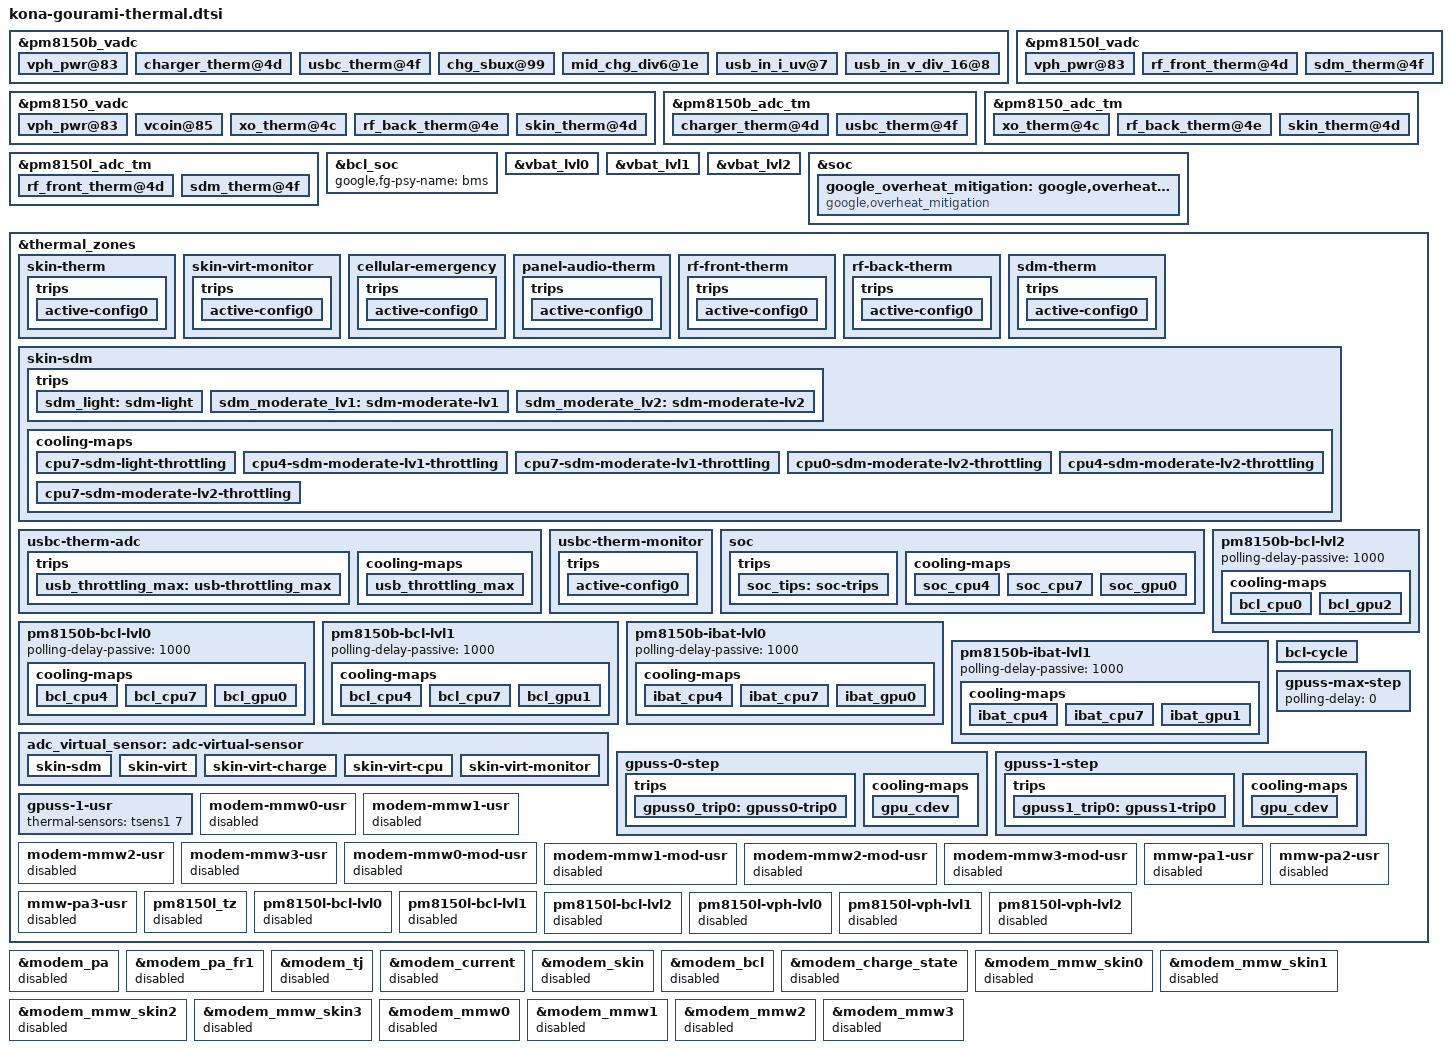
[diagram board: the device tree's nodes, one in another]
// SPDX-License-Identifier: GPL-2.0
/* Copyright (c) 2022, The Linux Foundation. All rights reserved.
 *
 * This program is free software; you can redistribute it and/or modify
 * it under the terms of the GNU General Public License version 2 and
 * only version 2 as published by the Free Software Foundation.
 *
 * This program is distributed in the hope that it will be useful,
 * but WITHOUT ANY WARRANTY; without even the implied warranty of
 * MERCHANTABILITY or FITNESS FOR A PARTICULAR PURPOSE.  See the
 * GNU General Public License for more details.
 */

#include <dt-bindings/thermal/thermal.h>

&pm8150b_vadc {
	#address-cells = <1>;
	#size-cells = <0>;

	vph_pwr@83 {
		reg = <ADC_VPH_PWR>;
		label = "vph_pwr";
		qcom,pre-scaling = <1 3>;
	};

	charger_therm@4d {
		reg = <ADC_AMUX_THM1_PU2>;
		label = "charger_therm";
		qcom,ratiometric;
		qcom,hw-settle-time = <200>;
		qcom,pre-scaling = <1 1>;
	};

	usbc_therm@4f {
		reg = <ADC_AMUX_THM3_PU2>;
		label = "usbc_therm";
		qcom,ratiometric;
		qcom,hw-settle-time = <200>;
		qcom,pre-scaling = <1 1>;
	};

	chg_sbux@99 {
		reg = <ADC_SBUx>;
		label = "chg_sbux";
		qcom,pre-scaling = <1 3>;
	};

	mid_chg_div6@1e {
		reg = <ADC_MID_CHG_DIV6>;
		label = "chg_mid";
		qcom,pre-scaling = <1 6>;
	};

	usb_in_i_uv@7 {
		reg = <ADC_USB_IN_I>;
		label = "usb_in_i_uv";
		qcom,pre-scaling = <1 1>;
	};

	usb_in_v_div_16@8 {
		reg = <ADC_USB_IN_V_16>;
		label = "usb_in_v_div_16";
		qcom,pre-scaling = <1 16>;
	};

	/delete-node/ smb1390_therm;
	/delete-node/ smb1355_therm;
};

&pm8150_vadc {
	#address-cells = <1>;
	#size-cells = <0>;

	vph_pwr@83 {
		reg = <ADC_VPH_PWR>;
		label = "vph_pwr";
		qcom,pre-scaling = <1 3>;
	};

	vcoin@85 {
		reg = <ADC_VCOIN>;
		label = "vcoin";
		qcom,pre-scaling = <1 3>;
	};

	xo_therm@4c {
		reg = <ADC_XO_THERM_PU2>;
		label = "xo_therm";
		qcom,ratiometric;
		qcom,hw-settle-time = <200>;
		qcom,pre-scaling = <1 1>;
	};

	rf_back_therm@4e {
		reg = <ADC_AMUX_THM2_PU2>;
		label = "rf_back_therm";
		qcom,ratiometric;
		qcom,hw-settle-time = <200>;
		qcom,pre-scaling = <1 1>;
	};

	skin_therm@4d {
		reg = <ADC_AMUX_THM1_PU2>;
		label = "skin_therm";
		qcom,ratiometric;
		qcom,hw-settle-time = <200>;
		qcom,pre-scaling = <1 1>;
	};
};

&pm8150l_vadc {
	#address-cells = <1>;
	#size-cells = <0>;

	vph_pwr@83 {
		reg = <ADC_VPH_PWR>;
		label = "vph_pwr";
		qcom,pre-scaling = <1 3>;
	};

	rf_front_therm@4d {
		reg = <ADC_AMUX_THM1_PU2>;
		label = "rf_front_therm";
		qcom,ratiometric;
		qcom,hw-settle-time = <200>;
		qcom,pre-scaling = <1 1>;
	};

	sdm_therm@4f {
		reg = <ADC_AMUX_THM3_PU2>;
		label = "sdm_therm";
		qcom,ratiometric;
		qcom,hw-settle-time = <200>;
		qcom,pre-scaling = <1 1>;
	};
};

&pm8150b_adc_tm {
	#address-cells = <1>;
	#size-cells = <0>;

	io-channels = <&pm8150b_vadc ADC_AMUX_THM1_PU2>,
			<&pm8150b_vadc ADC_AMUX_THM3_PU2>;

	/* Channel nodes */
	charger_therm@4d {
		reg = <ADC_AMUX_THM1_PU2>;
		qcom,ratiometric;
		qcom,hw-settle-time = <200>;
	};

	usbc_therm@4f {
		reg = <ADC_AMUX_THM3_PU2>;
		qcom,ratiometric;
		qcom,hw-settle-time = <200>;
	};
};

&pm8150_adc_tm {
	#address-cells = <1>;
	#size-cells = <0>;

	io-channels = <&pm8150_vadc ADC_XO_THERM_PU2>,
			<&pm8150_vadc ADC_AMUX_THM2_PU2>,
			<&pm8150_vadc ADC_AMUX_THM1_PU2>;

	xo_therm@4c {
		reg = <ADC_XO_THERM_PU2>;
		qcom,ratiometric;
		qcom,hw-settle-time = <200>;
	};

	rf_back_therm@4e {
		reg = <ADC_AMUX_THM2_PU2>;
		qcom,ratiometric;
		qcom,hw-settle-time = <200>;
	};

	skin_therm@4d {
		reg = <ADC_AMUX_THM1_PU2>;
		qcom,ratiometric;
		qcom,hw-settle-time = <200>;
	};
};

&pm8150l_adc_tm {
	#address-cells = <1>;
	#size-cells = <0>;

	io-channels = <&pm8150l_vadc ADC_AMUX_THM1_PU2>,
			<&pm8150l_vadc ADC_AMUX_THM3_PU2>;

	/* Channel nodes */
	rf_front_therm@4d {
		reg = <ADC_AMUX_THM1_PU2>;
		qcom,ratiometric;
		qcom,hw-settle-time = <200>;
	};

	sdm_therm@4f {
		reg = <ADC_AMUX_THM3_PU2>;
		qcom,ratiometric;
		qcom,hw-settle-time = <200>;
	};
};

&bcl_soc {
	google,fg-psy-name = "bms";
};

&vbat_lvl0 {
	temperature = <3200>;
	hysteresis = <200>;
	type = "passive";
};

&vbat_lvl1 {
	temperature = <3100>;
	hysteresis = <200>;
	type = "passive";
};

&vbat_lvl2 {
	temperature = <3000>;
	hysteresis = <200>;
	type = "passive";
};

&soc {
	google_overheat_mitigation: google,overheat_mitigation {
		compatible = "google,overheat_mitigation";
		google,port-overheat-work-interval = <2000>;
		google,begin-mitigation-temp = <480>;
		google,end-mitigation-temp = <400>;
		/* Must maintain < 1/15 duty cycle */
		google,polling-freq = <3>;
		#cooling-cells = <2>;
	};
};

&thermal_zones {
	/* Bring up common thermal zones for Gourami */
	skin-therm {
		polling-delay-passive = <0>;
		polling-delay = <0>;
		thermal-governor = "user_space";
		thermal-sensors = <&pm8150_adc_tm ADC_AMUX_THM1_PU2>;
		wake-capable-sensor;
		trips {
			active-config0 {
				temperature = <125000>;
				hysteresis = <1000>;
				type = "passive";
			};
		};
	};

	skin-virt-monitor {
		polling-delay-passive = <0>;
		polling-delay = <0>;
		thermal-governor = "user_space";
		wake-capable-sensor;
		//disable-thermal-zone;
		trips {
			active-config0 {
				temperature = <125000>;
				hysteresis = <1000>;
				type = "passive";
			};
		};
	};

	cellular-emergency {
		polling-delay-passive = <0>;
		polling-delay = <0>;
		thermal-governor = "user_space";
		thermal-sensors = <&pm8150l_adc_tm ADC_AMUX_THM1_PU2>;
		wake-capable-sensor;
		trips {
			active-config0 {
				temperature = <125000>;
				hysteresis = <1000>;
				type = "passive";
			};
		};
	};

	panel-audio-therm {
		polling-delay-passive = <0>;
		polling-delay = <0>;
		thermal-governor = "user_space";
		thermal-sensors = <&pm8150l_adc_tm ADC_AMUX_THM1_PU2>;
		wake-capable-sensor;
		trips {
			active-config0 {
				temperature = <125000>;
				hysteresis = <1000>;
				type = "passive";
			};
		};
	};

	rf-front-therm {
		polling-delay-passive = <0>;
		polling-delay = <0>;
		thermal-governor = "user_space";
		thermal-sensors = <&pm8150l_adc_tm ADC_AMUX_THM1_PU2>;
		wake-capable-sensor;
		trips {
			active-config0 {
				temperature = <125000>;
				hysteresis = <1000>;
				type = "passive";
			};
		};
	};

	rf-back-therm {
		polling-delay-passive = <0>;
		polling-delay = <0>;
		thermal-governor = "user_space";
		thermal-sensors = <&pm8150_adc_tm ADC_AMUX_THM2_PU2>;
		wake-capable-sensor;
		trips {
			active-config0 {
				temperature = <125000>;
				hysteresis = <1000>;
				type = "passive";
			};
		};
	};

	sdm-therm {
		polling-delay-passive = <0>;
		polling-delay = <0>;
		thermal-governor = "user_space";
		thermal-sensors = <&pm8150l_adc_tm ADC_AMUX_THM3_PU2>;
		wake-capable-sensor;
		trips {
			active-config0 {
				temperature = <125000>;
				hysteresis = <1000>;
				type = "passive";
			};
		};
	};

	skin-sdm {
		polling-delay-passive = <2000>;
		polling-delay = <0>;
		thermal-governor = "step_wise";
		wake-capable-sensor;
		trips {
			sdm_light: sdm-light {
				temperature = <63000>;
				hysteresis = <2000>;
				type = "passive";
			};
			sdm_moderate_lv1: sdm-moderate-lv1 {
				temperature = <65000>;
				hysteresis = <2000>;
				type = "passive";
			};
			sdm_moderate_lv2: sdm-moderate-lv2 {
				temperature = <67000>;
				hysteresis = <2000>;
				type = "passive";
			};
		};
		cooling-maps {
			/* sdm light throttling */
			cpu7-sdm-light-throttling {
				trip = <&sdm_light>;
				cooling-device =
				<&CPU7 1 1>;
			};
			/* sdm moderate throttling level 1 */
			cpu4-sdm-moderate-lv1-throttling {
				trip = <&sdm_moderate_lv1>;
				cooling-device =
				<&CPU4 1 2>;
			};
			cpu7-sdm-moderate-lv1-throttling {
				trip = <&sdm_moderate_lv1>;
				cooling-device =
				<&CPU7 2 4>;
			};
			/* sdm moderate throttling level 2 */
			cpu0-sdm-moderate-lv2-throttling {
				trip = <&sdm_moderate_lv2>;
				cooling-device =
				<&CPU0 1 2>;
			};
			cpu4-sdm-moderate-lv2-throttling {
				trip = <&sdm_moderate_lv2>;
				cooling-device =
				<&CPU4 2 3>;
			};
			cpu7-sdm-moderate-lv2-throttling {
				trip = <&sdm_moderate_lv2>;
				cooling-device =
				<&CPU7 4 5>;
			};
		};
	};

	usbc-therm-adc {
		polling-delay-passive = <0>;
		polling-delay = <0>;
		thermal-governor = "step_wise";
		thermal-sensors = <&pm8150b_adc_tm ADC_AMUX_THM3_PU2>;
		wake-capable-sensor;
		trips {
			usb_throttling_max: usb-throttling_max {
				temperature = <48000>;
				hysteresis = <10000>;
				type = "passive";
			};
		};
		cooling-maps {
			usb_throttling_max {
				trip = <&usb_throttling_max>;
				cooling-device =
					<&google_overheat_mitigation
					THERMAL_MAX_LIMIT THERMAL_MAX_LIMIT>;
			};
		};
	};

	usbc-therm-monitor {
		polling-delay-passive = <0>;
		polling-delay = <0>;
		thermal-governor = "user_space";
		thermal-sensors = <&pm8150b_adc_tm ADC_AMUX_THM3_PU2>;
		wake-capable-sensor;
		trips {
			active-config0 {
				temperature = <125000>;
				hysteresis = <1000>;
				type = "passive";
			};
		};
	};

	soc {
		polling-delay-passive = <60000>;
		polling-delay = <0>;
		thermal-governor = "low_limits_cap";
		thermal-sensors = <&bcl_soc>;
		tracks-low;
		wake-capable-sensor;

		trips {
			soc_tips: soc-trips {
				temperature = <10>;
				hysteresis = <0>;
				type = "passive";
			};
		};
		cooling-maps {
			soc_cpu4 {
				trip = <&soc_tips>;
				cooling-device =
					<&CPU4 11 11>;
			};
			soc_cpu7 {
				trip = <&soc_tips>;
				cooling-device =
					<&CPU7 11 11>;
			};
			soc_gpu0 {
				trip = <&soc_tips>;
				cooling-device = <&msm_gpu 4 4>;
			};
		};
	};

	pm8150b-bcl-lvl0 {
		polling-delay-passive = <1000>;
		cooling-maps {
			bcl_cpu4 {
				trip = <&b_bcl_lvl0>;
				cooling-device =
					<&CPU4 11 11>;
			};
			bcl_cpu7 {
				trip = <&b_bcl_lvl0>;
				cooling-device =
					<&CPU7 11 11>;
			};
			bcl_gpu0 {
				trip = <&b_bcl_lvl0>;
				cooling-device = <&msm_gpu 4 4>;
			};
		};
	};

	pm8150b-bcl-lvl1 {
		polling-delay-passive = <1000>;
		cooling-maps {
			bcl_cpu4 {
				trip = <&b_bcl_lvl1>;
				cooling-device =
					<&CPU4 THERMAL_MAX_LIMIT
					THERMAL_MAX_LIMIT>;
			};
			bcl_cpu7 {
				trip = <&b_bcl_lvl1>;
				cooling-device =
					<&CPU7 THERMAL_MAX_LIMIT
					THERMAL_MAX_LIMIT>;
			};
			bcl_gpu1 {
				trip = <&b_bcl_lvl1>;
				cooling-device = <&msm_gpu 6 6>;
			};
		};
	};

	pm8150b-bcl-lvl2 {
		polling-delay-passive = <1000>;
		cooling-maps {
			bcl_cpu0 {
				trip = <&b_bcl_lvl2>;
				cooling-device =
					<&CPU0 6 6>;
			};
			bcl_gpu2 {
				trip = <&b_bcl_lvl2>;
				cooling-device = <&msm_gpu THERMAL_MAX_LIMIT
							THERMAL_MAX_LIMIT>;
			};
		};
	};

	pm8150b-ibat-lvl0 {
		polling-delay-passive = <1000>;
		cooling-maps {
			ibat_cpu4 {
				trip = <&ibat_lvl0>;
				cooling-device =
					<&CPU4 11 11>;
			};
			ibat_cpu7 {
				trip = <&ibat_lvl0>;
				cooling-device =
					<&CPU7 11 11>;
			};
			ibat_gpu0 {
				trip = <&ibat_lvl0>;
				cooling-device = <&msm_gpu 4 4>;
			};
		};
	};

	pm8150b-ibat-lvl1 {
		polling-delay-passive = <1000>;
		cooling-maps {
			ibat_cpu4 {
				trip = <&ibat_lvl1>;
				cooling-device =
					<&CPU4 THERMAL_MAX_LIMIT
					THERMAL_MAX_LIMIT>;
			};
			ibat_cpu7 {
				trip = <&ibat_lvl1>;
				cooling-device =
					<&CPU7 THERMAL_MAX_LIMIT
					THERMAL_MAX_LIMIT>;
			};
			ibat_gpu1 {
				trip = <&ibat_lvl1>;
				cooling-device = <&msm_gpu 6 6>;
			};
		};
	};

	bcl-cycle {
		polling-delay-passive = <60000>;
		polling-delay = <0>;
		thermal-sensors = <&google_battery>;
	};

	adc_virtual_sensor: adc-virtual-sensor {
	};

	gpuss-max-step {
		polling-delay = <0>;
	};

	gpuss-0-step {
		polling-delay-passive = <10>;
		polling-delay = <0>;
		thermal-sensors = <&tsens0 15>;
		thermal-governor = "step_wise";
		wake-capable-sensor;
		trips {
			gpuss0_trip0: gpuss0-trip0 {
				temperature = <95000>;
				hysteresis = <1000>;
				type = "passive";
			};
		};
		cooling-maps {
			gpu_cdev {
				trip = <&gpuss0_trip0>;
				cooling-device = <&msm_gpu THERMAL_NO_LIMIT
							THERMAL_NO_LIMIT>;
			};
		};
	};

	gpuss-1-step {
		polling-delay-passive = <10>;
		polling-delay = <0>;
		thermal-sensors = <&tsens1 8>;
		thermal-governor = "step_wise";
		wake-capable-sensor;
		trips {
			gpuss1_trip0: gpuss1-trip0 {
				temperature = <95000>;
				hysteresis = <1000>;
				type = "passive";
			};
		};
		cooling-maps {
			gpu_cdev {
				trip = <&gpuss1_trip0>;
				cooling-device = <&msm_gpu THERMAL_NO_LIMIT
							THERMAL_NO_LIMIT>;
			};
		};
	};

	gpuss-1-usr {
		thermal-sensors = <&tsens1 7>;
	};

	/* Remove redundant QCT thermal zones */
	modem-mmw0-usr {
		status = "disabled";
	};

	modem-mmw1-usr {
		status = "disabled";
	};

	modem-mmw2-usr {
		status = "disabled";
	};

	modem-mmw3-usr {
		status = "disabled";
	};

	modem-mmw0-mod-usr {
		status = "disabled";
	};

	modem-mmw1-mod-usr {
		status = "disabled";
	};

	modem-mmw2-mod-usr {
		status = "disabled";
	};

	modem-mmw3-mod-usr {
		status = "disabled";
	};

	mmw-pa1-usr {
		status = "disabled";
	};

	mmw-pa2-usr {
		status = "disabled";
	};

	mmw-pa3-usr {
		status = "disabled";
	};

	pm8150l_tz {
		status = "disabled";
	};

	/* Disable PM8150l BCL */
	pm8150l-bcl-lvl0 {
		status = "disabled";
	};

	pm8150l-bcl-lvl1 {
		status = "disabled";
	};

	pm8150l-bcl-lvl2 {
		status = "disabled";
	};

	pm8150l-vph-lvl0 {
		status = "disabled";
	};

	pm8150l-vph-lvl1 {
		status = "disabled";
	};

	pm8150l-vph-lvl2 {
		status = "disabled";
	};
};

&adc_virtual_sensor {
	skin-sdm {
		logic = "weight";
		num_sensors = <2>;
		sensor-names = "skin-therm", "sdm-therm";
		coefficients = <1 1>;
		avg-offset = <0>;
		avg-denominator = <2>;
	};

	skin-virt {
		logic = "weight";
		num_sensors = <2>;
		sensor-names = "skin-therm", "usbc-therm-adc";
		coefficients = <1 1>;
		avg-offset = <(-2500)>;
		avg-denominator = <2>;
	};

	skin-virt-charge {
		logic = "weight";
		num_sensors = <3>;
		sensor-names = "skin-therm", "sdm-therm", "usbc-therm-adc";
		coefficients = <1 1 2>;
		avg-offset = <0>;
		avg-denominator = <4>;
	};

	skin-virt-cpu {
		logic = "weight";
		num_sensors = <2>;
		sensor-names = "skin-therm", "usbc-therm-adc";
		coefficients = <1 1>;
		avg-offset = <(-2500)>;
		avg-denominator = <2>;
	};

	skin-virt-monitor {
		logic = "weight";
		num_sensors = <2>;
		sensor-names = "skin-therm", "usbc-therm-adc";
		coefficients = <1 1>;
		avg-offset = <(-2500)>;
		avg-denominator = <2>;
	};
};

/* Remove redundant QCT thermal zones */
&modem_pa {
	status = "disabled";
};

&modem_pa_fr1 {
	status = "disabled";
};

&modem_tj {
	status = "disabled";
};

&modem_current {
	status = "disabled";
};

&modem_skin {
	status = "disabled";
};

&modem_bcl {
	status = "disabled";
};

&modem_charge_state {
	status = "disabled";
};

&modem_mmw_skin0 {
	status = "disabled";
};

&modem_mmw_skin1 {
	status = "disabled";
};

&modem_mmw_skin2 {
	status = "disabled";
};

&modem_mmw_skin3 {
	status = "disabled";
};

&modem_mmw0 {
	status = "disabled";
};

&modem_mmw1 {
	status = "disabled";
};

&modem_mmw2 {
	status = "disabled";
};

&modem_mmw3 {
	status = "disabled";
};
